# NUC505_v1 register map
File version: 1.0
Registers are 32-bit, read-write, reset 0x0 unless marked. A register's access mark holds for its fields unless they carry their own. Offsets are from the block's base; [hi:lo] are bit positions; lines under a group give offsets from that group; {n}, {i} and the like mark numbered series; 'fields as' and 'values as' point back to an identical list.

## GPIO — GPIO Register Map
Base 0x400E3000
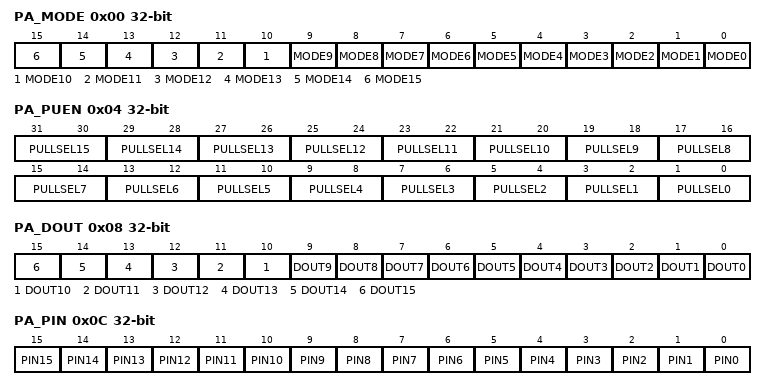
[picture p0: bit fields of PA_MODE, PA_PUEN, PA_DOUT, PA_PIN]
0x00 PA_MODE — PA I/O Mode Control
  [all] fields
    0=Px.n is in Input mode; 1=Px.n is in Push-pull Output mode
  [n] MODE{n} (n=0..15) — Port A-d I/O Pin[N] Mode Control. Determine each I/O mode of Px.n pins.
0x04 PA_PUEN — PA I/O Pull-up/Down Resistor Control
  [all] fields
    0=Px.n pull-up or pull-down resistors are all Disabled; 1=Px.n pull-up resistor Enabled; 2=Px.n pull-down resistor Enabled
  [2n+1:2n] PULLSEL{n} (n=0..15) — Port A-d Pin Pull-up Resistor or Pull-down Resistor Enable Control. Note2: Refer to Figure 6.41
0x08 PA_DOUT — PA Data Output Value
  [all] fields
    0=Px.n will drive Low if the Px.n pin is configured as Push-pull output mode; 1=Px.n will drive High if the Px.n pin is configured as Push-pull output mode
  [n] DOUT{n} (n=0..15) — Port A-d Pin[N] Output Value. Each of these bits controls the status of a Px.n pin when the Px.n is configured as Push-pull output mode.
0x0C PA_PIN ro (reset mask 0xFFFF0000) — PA Pin Value
  [n] PIN{n} (n=0..15) — Port A-d Pin[N] Pin Value. Each bit of the register reflects the actual status of the respective Px.n pin. If the bit is 1, it indicates the corresponding pin status is high; else the pin status is low. Note:
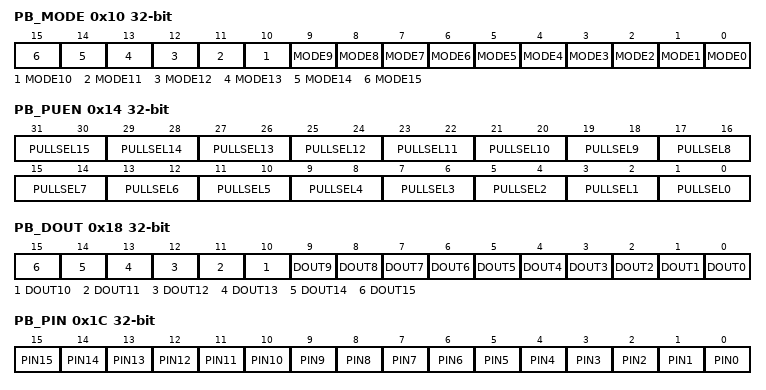
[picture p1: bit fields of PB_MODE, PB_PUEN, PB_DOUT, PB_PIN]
0x10 PB_MODE — PB I/O Mode Control
  fields as PA_MODE
0x14 PB_PUEN — PB I/O Pull-up/Down Resistor Control
  fields as PA_PUEN
0x18 PB_DOUT — PB Data Output Value
  fields as PA_DOUT
0x1C PB_PIN ro (reset mask 0xFFFF0000) — PB Pin Value
  fields as PA_PIN
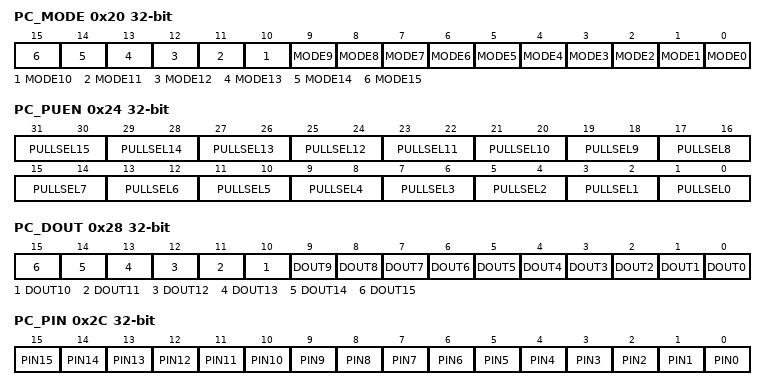
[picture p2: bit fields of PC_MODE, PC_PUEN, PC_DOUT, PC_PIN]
0x20 PC_MODE — PC I/O Mode Control
  fields as PA_MODE
0x24 PC_PUEN — PC I/O Pull-up/Down Resistor Control
  fields as PA_PUEN
0x28 PC_DOUT — PC Data Output Value
  fields as PA_DOUT
0x2C PC_PIN ro (reset mask 0xFFFF0000) — PC Pin Value
  fields as PA_PIN
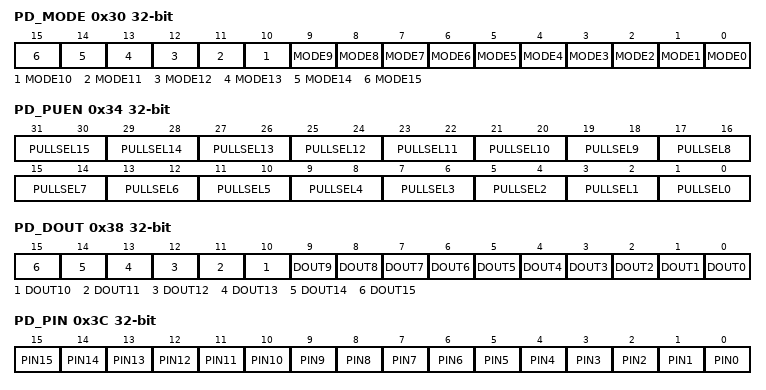
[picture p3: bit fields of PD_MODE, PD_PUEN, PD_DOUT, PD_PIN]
0x30 PD_MODE — PD I/O Mode Control
  fields as PA_MODE
0x34 PD_PUEN — PD I/O Pull-up/Down Resistor Control
  fields as PA_PUEN
0x38 PD_DOUT — PD Data Output Value
  fields as PA_DOUT
0x3C PD_PIN ro (reset mask 0xFFFF0000) — PD Pin Value
  fields as PA_PIN
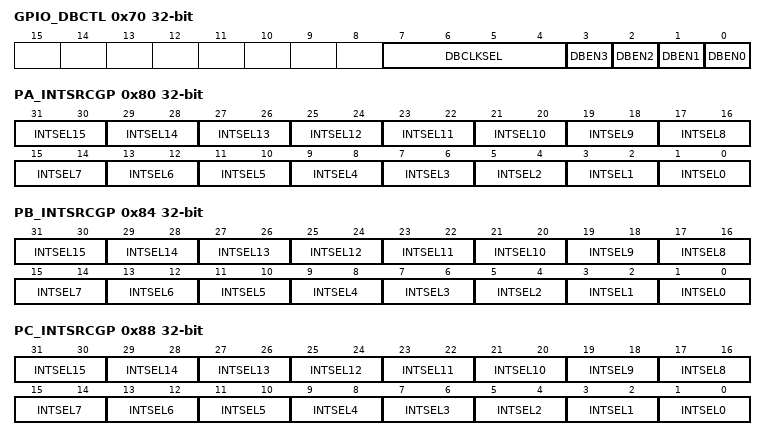
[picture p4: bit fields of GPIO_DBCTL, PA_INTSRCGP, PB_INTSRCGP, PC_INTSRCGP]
0x70 GPIO_DBCTL — Interrupt Event (EINT) De-bounce Control
  [7:4] DBCLKSEL — De-bounce Sampling Cycle Selection
    0=Sample interrupt input once per 1 APB clocks; 1=Sample interrupt input once per 2 APB clocks; 2=Sample interrupt input once per 4 APB clocks; 3=Sample interrupt input once per 8 APB clocks; 4=Sample interrupt input once per 16 APB clocks; 5=Sample interrupt input once per 32 APB clocks; 6=Sample interrupt input once per 64 APB clocks; 7=Sample interrupt input once per 128 APB clocks; 8=Sample interrupt input once per 256 APB clocks; 9=Sample interrupt input once per 512 APB clocks; 10=Sample interrupt input once per 1024 APB clocks; 11=Sample interrupt input once per 2048 APB clocks; 12=Sample interrupt input once per 4096 APB clocks; 13=Sample interrupt input once per 8192 APB clocks; 14=Sample interrupt input once per 16384 APB clocks; 15=Sample interrupt input once per 32768 APB clocks
  [n] DBEN{n} (n=0..3) — EINT (EINT0~EINT3) De-bounce Enable Control. The DBEN[n] bit is used to enable the de-bounce function for each corresponding EINT. If the input signal pulse width cannot be sampled by continuous two de-bounce sample cycle, the input signal transition is regarded as the signal bounce and will not trigger the interrupt. The de- bounce sample cycle period is controlled by DBCLKSEL (GPIO_DBCTL [7:4]).
    0=EINTn de-bounce function Disabled; 1=EINTn de-bounce function Enabled
0x80 PA_INTSRCGP — PA Interrupt Event (EINT) Source Grouping
  [all] fields
    {v}=Px.n pin is selected as one of interrupt sources to EINT{v} (v=0..3)
  [2n+1:2n] INTSEL{n} (n=0..15) — Selection for Px.N As One of Interrupt Sources to EINT0, EINT1, EINT2, or EINT3
0x84 PB_INTSRCGP — PB Interrupt Event (EINT) Source Grouping
  fields as PA_INTSRCGP
0x88 PC_INTSRCGP — PC Interrupt Event (EINT) Source Grouping
  fields as PA_INTSRCGP
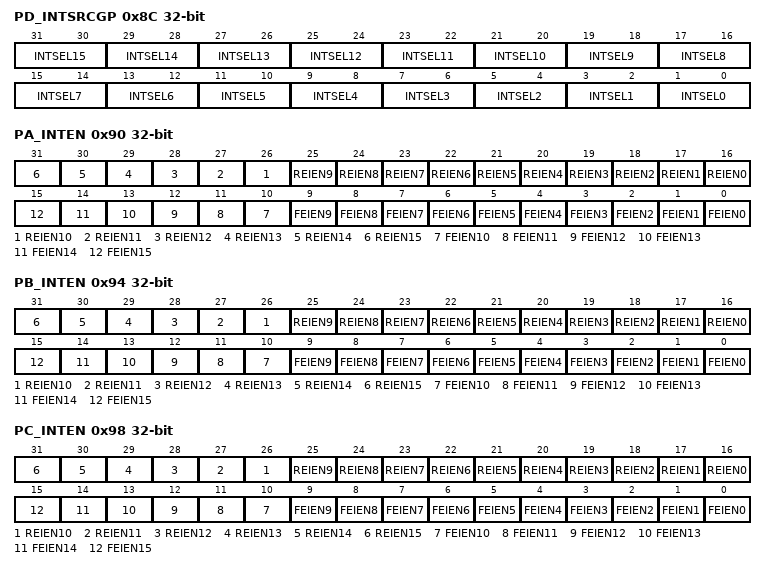
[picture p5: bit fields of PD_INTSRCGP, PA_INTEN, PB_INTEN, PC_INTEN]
0x8C PD_INTSRCGP — PD Interrupt Event (EINT) Source Grouping
  fields as PA_INTSRCGP
0x90 PA_INTEN — PA Interrupt Enable Control Register
  [n+16] REIEN{n} (n=0..15) — Port A-d Pin[N] Control Rising Edge of Input Px.N Pin to Trigger the Interrupt. The RHIEN (Px_INTEN[n+16]) bit is used to enable the interrupt for each of the corresponding input Px.n pin. Set bit to 1 also enable the pin wake-up function. When setting the RHIEN (Px_INTEN[n+16]) bit to 1 : The input Px.n pin will generate the interrupt while this pin state changed from low to high.
    0=Px.n low to high interrupt Disabled; 1=Px.n low to high interrupt Enabled
  [n] FEIEN{n} (n=0..15) — Port A-d Pin[N] Control Falling Edge of Input Px.N Pin to Trigger the Interrupt. The FLIEN (Px_INTEN[n]) bit is used to enable the interrupt for each of the corresponding input Px.n pin. Set bit to 1 also enable the pin wake-up function. When setting the FLIEN (Px_INTEN[n]) bit to 1 : The input Px.n pin will generate the interrupt while this pin state changed from high to low.
    0=Px.n high to low interrupt Disabled; 1=Px.n high to low interrupt Enabled
0x94 PB_INTEN — PB Interrupt Enable Control Register
  fields as PA_INTEN
0x98 PC_INTEN — PC Interrupt Enable Control Register
  fields as PA_INTEN
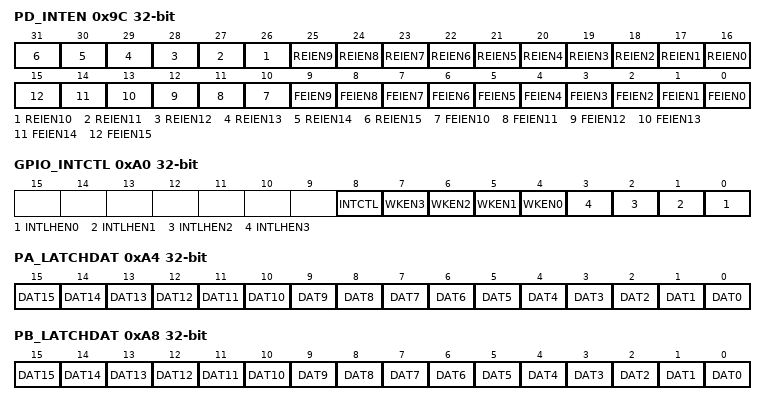
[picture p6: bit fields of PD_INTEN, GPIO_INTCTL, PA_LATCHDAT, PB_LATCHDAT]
0x9C PD_INTEN — PD Interrupt Enable Control Register
  fields as PA_INTEN
0xA0 GPIO_INTCTL — Interrupt Latch Trigger Selection Register
  [8] INTCTL — Interrupt Request Source Control
    0=When the GPIO interrupt occurs, the GPIO interrupt controller generates 1 APB clock pulse to the NVIC; 1=When the GPIO interrupt occurs, the interrupt from GPIO to NVIC will keep till the CPU clear the interrupt trigger source. (GPIO_INTSTSA_B, GPIO_INTSTSC_D)
  [n+4] WKEN{n} (n=0..3) — GPIO Interrupt Wake Up System Enable Control
    0=No effect; 1=EINTn can wake up the chip from Idle and Power-down mode
  [n] INTLHEN{n} (n=0..3) — Enable Latch PA.N/PB.N/PC.N/PD.N Value When EINTn Happen
    0=No effect; 1=When EINTn interrupt has happened, PA_LATCHDAT, PB_LATCHDAT, PC_LATCHDAT, and PD_LATCHDAT registers will latch PA, PB, PC, and PD port values within EINTn group
0xA4 PA_LATCHDAT ro — PA Interrupt Latch Value
  [n] DAT{n} (n=0..15) — Latch Px.N Interrupt Value. Latched value of Px.n while the EINT (EINT0~EINT3) selected by GPIO_INTCTL is active. Note:
0xA8 PB_LATCHDAT ro — PB Interrupt Latch Value
  fields as PA_LATCHDAT
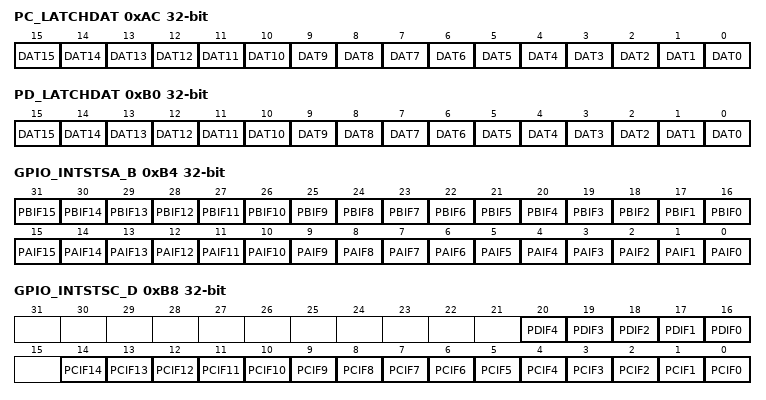
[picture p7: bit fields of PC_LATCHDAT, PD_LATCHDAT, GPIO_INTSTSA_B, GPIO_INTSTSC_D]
0xAC PC_LATCHDAT ro — PC Interrupt Latch Value
  fields as PA_LATCHDAT
0xB0 PD_LATCHDAT ro — PD Interrupt Latch Value
  fields as PA_LATCHDAT
0xB4 GPIO_INTSTSA_B — EINT0~3 Interrupt Trigger Source Indicator From PA and PB
  [n+16] PBIF{n} (n=0..15) — Port B Pin[N] Interrupt Source Flag. Write Operation:
    0=No action. No interrupt at PB.n1 = PB.n generates an interrupt; 1=Clear the corresponding pending interrupt
  [n] PAIF{n} (n=0..15) — Port a Pin[N] Interrupt Source Flag. Write Operation: When this bit is read as "1", it indicates that PA.n is a trigger source to generate the interrupt. Note: Write 1 to clear the correspond interrupt source
    0=No action. No interrupt at PA.n; 1=Clear the corresponding pending interrupt. PA.n generates an interrupt
0xB8 GPIO_INTSTSC_D — EINT0~3 Interrupt Trigger Source Indicator From PC and PD
  [n+16] PDIF{n} (n=0..4) — Port D Pin[N] Interrupt Source Flag. Write Operation:
    0=No action. No interrupt at PD.n; 1=Clear the corresponding pending interrupt. PD.n generates an interrupt
  [n] PCIF{n} (n=0..14) — Port C Pin[N] Interrupt Source Flag. Write Operation:
    0=No action. No interrupt at PC.n; 1=Clear the corresponding pending interrupt. PC.n generates an interrupt
